# PCIE1_CORE_USER_CFG_USER_CFG register map
Vendor: Texas Instruments
Peripheral module from a debugger description file (folder J7VCL).
Registers are 32-bit, read-only, reset 0x0 unless marked. A register's access mark holds for its fields unless they carry their own. Offsets are as the file gives them; lines under a group give offsets from that group; [hi:lo] are bit positions; {n}, {i} and the like mark numbered series; 'fields as' and 'values as' point back to an identical list; <NAME> marks a mode.

## PCIE1_CORE_USER_CFG_USER_CFG
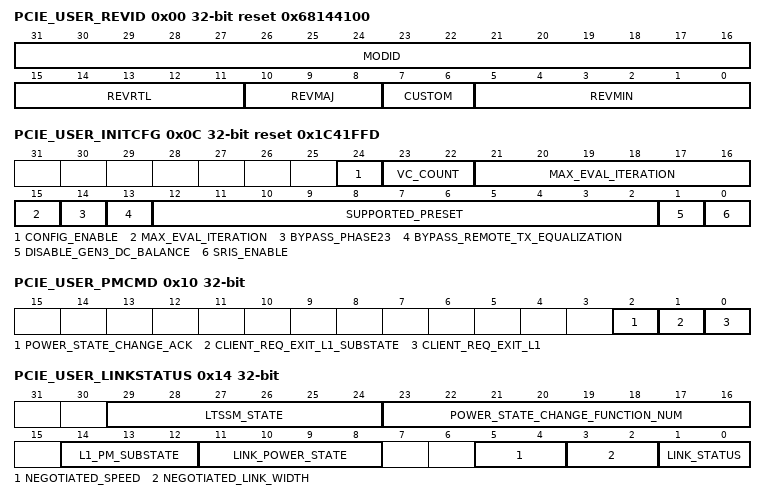
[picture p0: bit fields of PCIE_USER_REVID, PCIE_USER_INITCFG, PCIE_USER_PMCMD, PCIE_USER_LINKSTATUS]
0x00 PCIE_USER_REVID reset 0x68144100 — Module ID register
  [31:16] MODID — Module ID field
  [15:11] REVRTL — RTL revision.
  [10:8] REVMAJ — Major revision
  [7:6] CUSTOM
  [5:0] REVMIN — Minor revision
0x04 PCIE_USER_CMD_STATUS rw — Command Status register
  [0] LINK_TRAINING_ENABLE — This bit must be set to 1 to enable the LTSSM to bring up the link.
0x08 PCIE_USER_RSTCMD rw — Reset Command and Status register
  [0] INIT_HOT_RESET — When this bit is set to 1'b1 in the RP mode, the core initiates a Hot Reset sequence on the PCIe link.
0x0C PCIE_USER_INITCFG rw reset 0x1C41FFD — Initialization configuration register
  [24] CONFIG_ENABLE — When this bit is set to 0 in the EP mode, the Controller will generate a CRS Completion in response to Configuration Requests.
  [23:22] VC_COUNT — Number of VCs configured.
  [21:15] MAX_EVAL_ITERATION — Denotes the maximum number of iterations to be performed during the DirectionChange Feedback Link Equalization in case the direction change feedback does not converge to 00.
  [14] BYPASS_PHASE23 — This MMR should be programmed during system boot or initialization.
  [13] BYPASS_REMOTE_TX_EQUALIZATION — This MMR should be programmed during system boot or initialization.
  [12:2] SUPPORTED_PRESET — This MMR should be programmed during system boot or initialization.
  [1] DISABLE_GEN3_DC_BALANCE — This bit it is used to disable the transmission of special DC Balance symbols in TS1 training sequences for improving the DC balance of the bit stream at 8.0 GT/s or higher speed.
  [0] SRIS_ENABLE — Should be set as per the System Reference Clocking Implementation.
0x10 PCIE_USER_PMCMD rw — Power Management command register
  [2] POWER_STATE_CHANGE_ACK — Software must assert this bit for a minimum of one cycle in response to the assertion of POWER_STATE_CHANGE_INTERRUPT, when it is ready to transition to the low-power state requested by the configuration write request.
  [1] CLIENT_REQ_EXIT_L1_SUBSTATE — Client logic can trigger an explicit L
  [0] CLIENT_REQ_EXIT_L1 — Client logic can trigger an explicit L1 exit by setting this bit.
0x14 PCIE_USER_LINKSTATUS — Link Status register
  [29:24] LTSSM_STATE — Current state of the Link Training and Status State Machine within the core.
  [23:16] POWER_STATE_CHANGE_FUNCTION_NUM — Function number of the function for which a power state change occurred.
  [14:12] L1_PM_SUBSTATE — This register provides the current state of the L1 PM substates state machine.
  [11:8] LINK_POWER_STATE — Current power state of the PCIe link.
  [5:4] NEGOTIATED_SPEED — Current operating speed of the link is as follows:
  [3:2] NEGOTIATED_LINK_WIDTH — Current link width are as follows:
  [1:0] LINK_STATUS — Status of the PCI Express link.
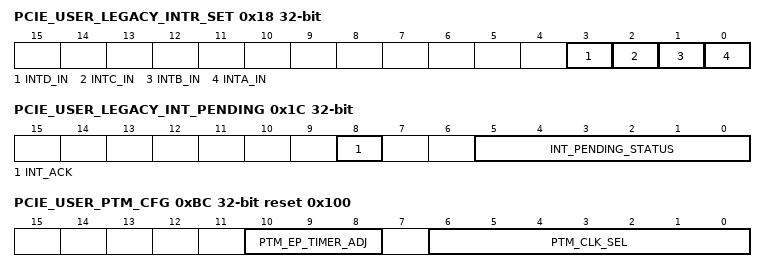
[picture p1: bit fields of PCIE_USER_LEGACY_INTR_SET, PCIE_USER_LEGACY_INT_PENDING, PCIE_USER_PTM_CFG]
0x18 PCIE_USER_LEGACY_INTR_SET rw — Legacy interrupt set register
  [3] INTD_IN — When the core is configured as EP, this bit is used by the client application to signal an interrupt from any of its PCI Functions to the RP using the Legacy PCI Express Interrupt Delivery mechanism of PCI Express.
  [2] INTC_IN — When the core is configured as EP, this bit is used by the client application to signal an interrupt from any of its PCI Functions to the RP using the Legacy PCI Express Interrupt Delivery mechanism of PCI Express.
  [1] INTB_IN — When the core is configured as EP, this bit is used by the client application to signal an interrupt from any of its PCI Functions to the RP using the Legacy PCI Express Interrupt Delivery mechanism of PCI Express.
  [0] INTA_IN — When the core is configured as EP, this bit is used by the client application to signal an interrupt from any of its PCI Functions to the RP using the Legacy PCI Express Interrupt Delivery mechanism of PCI Express.
0x1C PCIE_USER_LEGACY_INT_PENDING access not given — Legacy interrupt pending set register
  [8] INT_ACK — When using legacy interrupts, this bit indicates that the core has sent an INTx Assert or Deassert message in response to a change in the state of one of the INTx inputs. (access RW1C)
  [5:0] INT_PENDING_STATUS rw — When using legacy interrupts, this input is used to indicate the interrupt pending status of the Physical Functions. The bit i must be set when an interrupt is pending in Function i.
0x20 PCIE_USER_MSI_STAT — MSI status register
  [5:0] MSI_ENABLE — When the core is configured in the EndPoint mode to support MSI interrupts, this output is driven by the MSI Enable bit of the MSI Control Registers of the Physical Functions.
0x24 PCIE_USER_MSI_VECTOR — MSI vector register
  [17:0] MSI_VECTOR_COUNT — When the core is configured in the EndPoint mode to support MSI interrupts, these outputs are driven by the Multiple Message Enable bits of the MSI Control Registers associated with Physical Functions.
{0x28+4i} PCIE_USER_MSI_MASK_PF{i} (i=0..5) — PF{i} MSI mask register
  [31:0] MSI_MASK_PF{i} — These bits provide the setting of the MSI Mask registers of the Physical Function{i}.
0x40 PCIE_USER_MSI_PENDING_STATUS_PF0 rw — PF0 MSI pending status input register
  [31:0] MSI_PENDING_STATUS_PF0 — These inputs provide the status of the MSI pending interrupts for the Physical Function0 from the client to the core.
{0x40+4i} PCIE_USER_MSI_PENDING_STATUS_PF{i} rw (i=1..5) — PF{i} MSI pending status input register
  [31:0] MSI_PENDING_STATUS_PF{i} — These inputs provide the status of the MSI pending interrupts for the Physical Function1 from the client to the core, if MSI Pending Status In Mode Select is set to 1 in the Debug Mux Control 2 register in local management,the setting of this register determines the value read from the MSI Pending Bits Register PF{i}.
0x58 PCIE_USER_MSI_STAT_VF — MSI_VF status register
  [15:0] VF_MSI_ENABLE — When the core is configured in the EndPoint mode to support MSI interrupts, this output is driven by the MSI Enable bit of the MSI Control Registers of the Virtual Functions.
0x5C PCIE_USER_MSI_VECTOR0_VF — MSI_VF vector count register0
  [23:0] VF_MSI_VECTOR_COUNT0 — When the core is configured in the Endpoint mode to support MSI interrupts, these outputs are driven by the Multiple Message Enable bits of the MSI Control Registers associated with Virtual Function0 thru Virtual Function7.
0x60 PCIE_USER_MSI_VECTOR1_VF — MSI_VF vector count register1
  [23:0] VF_MSI_VECTOR_COUNT1 — When the core is configured in the Endpoint mode to support MSI interrupts, these outputs are driven by the Multiple Message Enable bits of the MSI Control Registers associated with Virtual Function8 thru Virtual Function15.
{0x64+4i} PCIE_USER_MSI_MASK_VF{i} (i=0..15) — VF{i}MSI mask register
  [31:0] MSI_MASK_VF{i} — These bits provide the setting of the MSI Mask registers of the Virtual Function{i}.
0xA4 PCIE_USER_MSIX_STAT — MSIX status register
  [5:0] MSIX_ENABLE — These bits reflect the states of the MSI-X Enable bits in the PCI configuration space of Physical Functions.Bit0 represents the MSIX Enable for Physical Function0 and Bit1 represents the MSIX Enable for Physical Function 1
0xA8 PCIE_USER_MSIX_MASK — MSIX mask register
  [5:0] MSIX_MASK — These bits reflect the states of the MSI-X Function Mask bits in the PCI configuration space of Physical Functions.
0xAC PCIE_USER_MSIX_STAT_VF — Virtual Function MSIX status register
  [15:0] VF_MSIX_ENABLE — These bits reflect the states of the MSI-X Enable bits in the PCI configuration space of virtual Functions.Bit0 represents the MSIX Enable for Virtual Function0, Bit1 represents the MSIX Enable for Virtual Function 1 and so on
0xB0 PCIE_USER_MSIX_MASK_VF — Virtual Function MSIX mask register
  [15:0] VF_MSIX_MASK — These bits reflect the states of the MSI-X Function Mask bits in the PCI configuration space of Virtual Functions.
0xB4 PCIE_USER_FLR_DONE wo — Physical Function-Level Reset Done register
  [5:0] FLR_DONE — These bits are connected to the
0xB8 PCIE_USER_VF_FLR_DONE wo — Virtual Function-Level Reset Done register
  [15:0] VF_FLR_DONE — These bits are connected to the
0xBC PCIE_USER_PTM_CFG access per field reset 0x100 — Return to the . PTM Timestamp configuration register
  [10:8] PTM_EP_TIMER_ADJ rw — PTM EP Timer tick adjust value. 1 will increment ptm_ep_timer by 1 each clock cycle, 2 will increment the timer by 2 .. 7 will increment the timer by 7. The adjust value should be set prior to enabling PTM operation in the PCIe controller.
  [6:0] PTM_CLK_SEL rw — Select CPTS HW1 push input. 0 will select ptm_local_timer[0], 1 will select ptm_local_timer[1] ... 63 will select ptm_local_timer[63] and 64 will select ptm_local_timer_out_valid. The values 65 to 127 are unused. The PTM clock select bit should be set prior to enabling the PTM operation in the PCIe controller
0xC0 PCIE_USER_PTM_TIMER_LOW — PTM timer value lower 32-bits
  [31:0] PTM_TIMER_OUT_LOW — ptm_timer_out[31:0] value from PCIe core.
0xC4 PCIE_USER_PTM_TIMER_HIGH — PTM timer value upper 32-bits
  [31:0] PTM_TIMER_OUT_HIGH — ptm_timer_out[63:32] value from PCIe core.
0xC8 PCIE_USER_EOI_VECTOR access per field — Return to the . EOI vector for re-triggering interrupts
  [7:0] EOI_VECTOR rw — EOI vector for level interrupts. Writing the EOI value as specfied to this register will re-trigger a pending interrupt. 0 - Downstream interrupt 1 - FLR interrupt 2 - Legacy interrupt 3 - Power state interrupt
